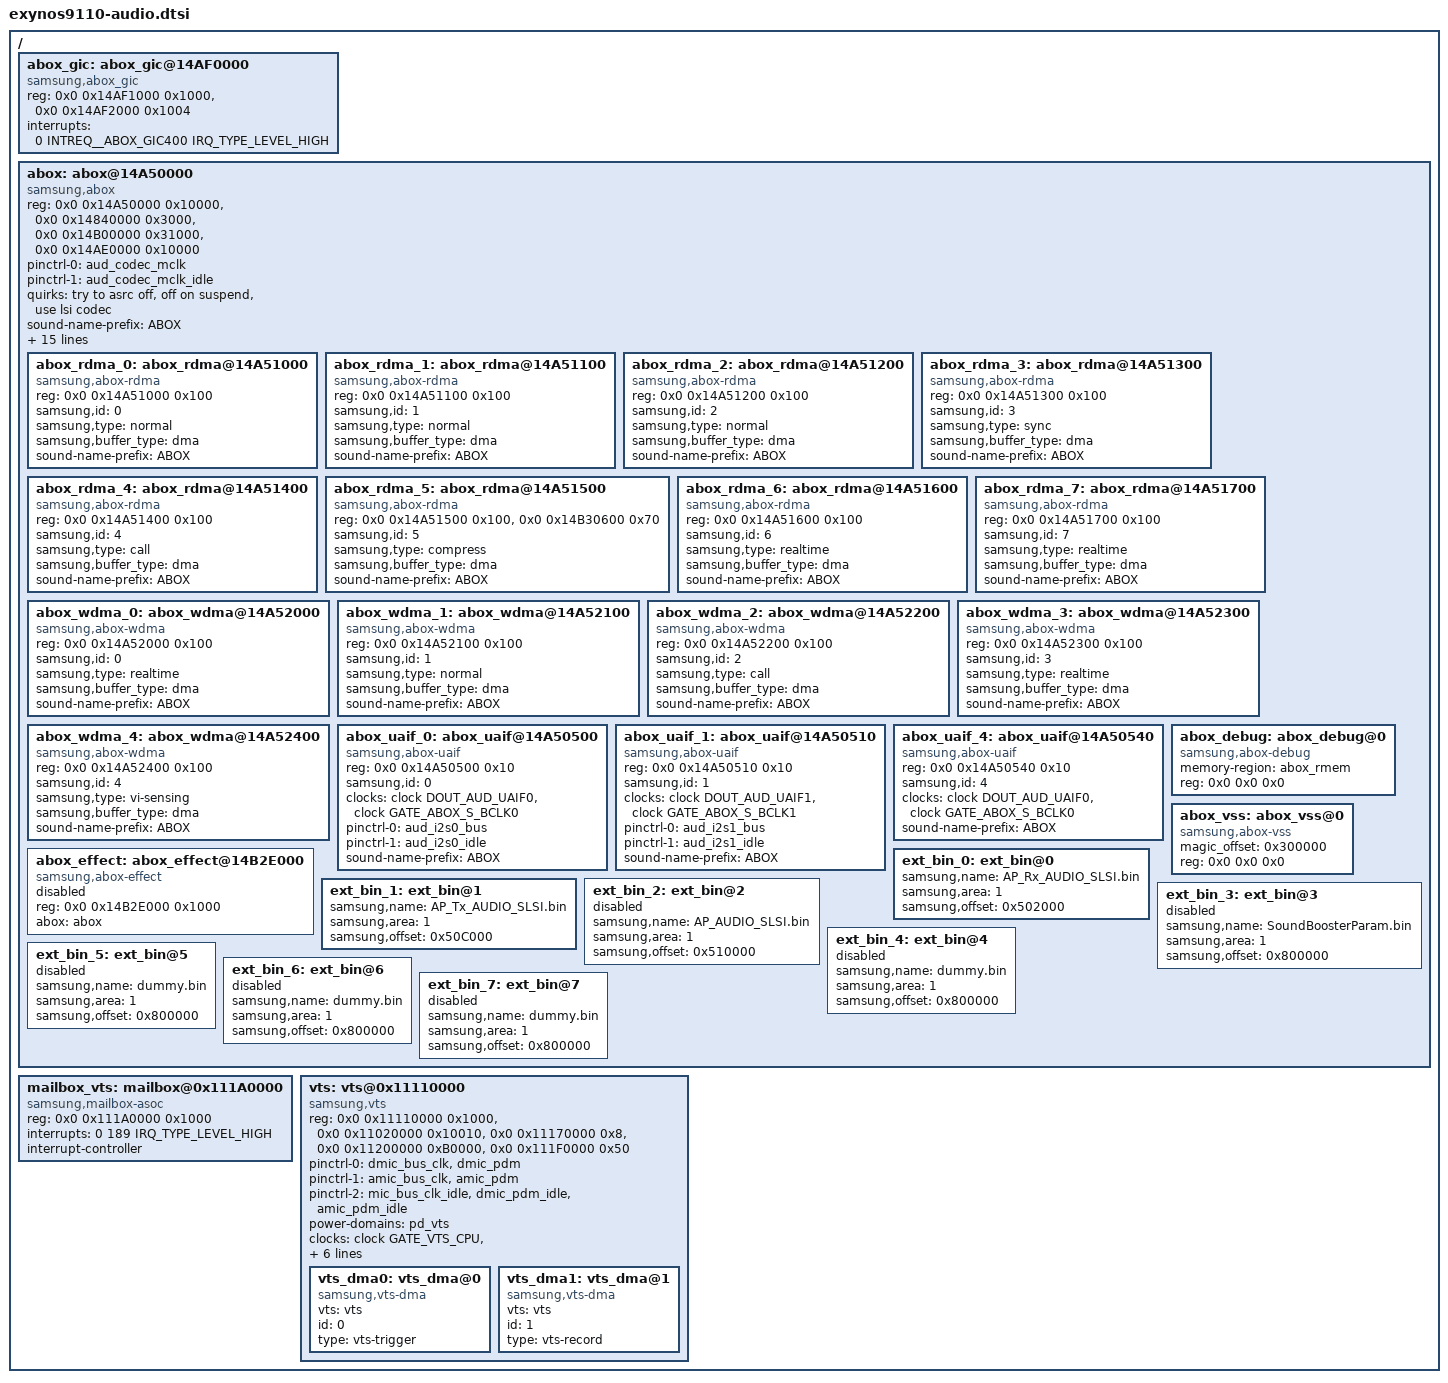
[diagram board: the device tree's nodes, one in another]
/*
 * SAMSUNG EXYNOS device tree source for reserved-memory
 *
 * Copyright (c) 2020 Samsung Electronics Co., Ltd.
 *		http://www.samsung.com
 *
 * This program is free software; you can redistribute it and/or modify
 * it under the terms of the GNU General Public License version 2 as
 * published by the Free Software Foundation.
 */

/ {
	abox_gic: abox_gic@14AF0000 {
		compatible = "samsung,abox_gic";
		reg = <0x0 0x14AF1000 0x1000>, <0x0 0x14AF2000 0x1004>;
		reg-names = "gicd", "gicc";
		interrupts = <0 INTREQ__ABOX_GIC400 IRQ_TYPE_LEVEL_HIGH>;
	};

	abox: abox@14A50000 {
		compatible = "samsung,abox";
		reg = <0x0 0x14A50000 0x10000>, <0x0 0x14840000 0x3000>,
			<0x0 0x14B00000 0x31000>, <0x0 0x14AE0000 0x10000>;
		reg-names = "sfr", "sysreg", "sram", "timer";
		#address-cells = <2>;
		#size-cells = <1>;
		ranges;
		pinctrl-names = "default", "idle";
		pinctrl-0 = <&aud_codec_mclk>;
		pinctrl-1 = <&aud_codec_mclk_idle>;
		quirks = "try to asrc off", "off on suspend", "use lsi codec";
		#sound-dai-cells = <1>;
		sound-name-prefix = "ABOX";
		samsung,power-domain = <&pd_dispaud>;
		ipc_tx_offset = <0x30000>;
		ipc_rx_offset = <0x30300>;
		ipc_tx_ack_offset = <0x302FC>;
		ipc_rx_ack_offset = <0x305FC>;
		abox_gic = <&abox_gic>;
		clocks = <&clock PLL_OUT_AUD>, <&clock GATE_ABOX_CPU>,
			<&clock DOUT_AUD_AUDIF>, <&clock DOUT_AUD_ACLK>;
		clock-names = "pll", "cpu", "audif", "bus";
		uaif_max_div = <512>;
		iommus = <&sysmmu_abox>;
		pm_qos_int = <0 0 0 0 0>;
		pm_qos_aud = <1180000 800000 590000 394000 0>;
		samsung,abox-bootargs = "init=ab0x vss=1";
		samsung,abox-bootargs-offset = <0x30E00>;

		abox_rdma_0: abox_rdma@14A51000 {
			compatible = "samsung,abox-rdma";
			reg = <0x0 0x14A51000 0x100>;
			reg-names = "sfr";
			samsung,id = <0>;
			samsung,type = "normal";
			samsung,buffer_type = "dma";
			#sound-dai-cells = <1>;
			sound-name-prefix = "ABOX";
		};

		abox_rdma_1: abox_rdma@14A51100 {
			compatible = "samsung,abox-rdma";
			reg = <0x0 0x14A51100 0x100>;
			reg-names = "sfr";
			samsung,id = <1>;
			samsung,type = "normal";
			samsung,buffer_type = "dma";
			#sound-dai-cells = <1>;
			sound-name-prefix = "ABOX";
		};

		abox_rdma_2: abox_rdma@14A51200 {
			compatible = "samsung,abox-rdma";
			reg = <0x0 0x14A51200 0x100>;
			reg-names = "sfr";
			samsung,id = <2>;
			samsung,type = "normal";
			samsung,buffer_type = "dma";
			#sound-dai-cells = <1>;
			sound-name-prefix = "ABOX";
		};

		abox_rdma_3: abox_rdma@14A51300 {
			compatible = "samsung,abox-rdma";
			reg = <0x0 0x14A51300 0x100>;
			reg-names = "sfr";
			samsung,id = <3>;
			samsung,type = "sync";
			samsung,buffer_type = "dma";
			#sound-dai-cells = <1>;
			sound-name-prefix = "ABOX";
		};

		abox_rdma_4: abox_rdma@14A51400 {
			compatible = "samsung,abox-rdma";
			reg = <0x0 0x14A51400 0x100>;
			reg-names = "sfr";
			samsung,id = <4>;
			samsung,type = "call";
			samsung,buffer_type = "dma";
			#sound-dai-cells = <1>;
			sound-name-prefix = "ABOX";
		};

		abox_rdma_5: abox_rdma@14A51500 {
			compatible = "samsung,abox-rdma";
			reg = <0x0 0x14A51500 0x100>, <0x0 0x14B30600 0x70>;
			reg-names = "sfr";
			samsung,id = <5>;
			samsung,type = "compress";
			samsung,buffer_type = "dma";
			#sound-dai-cells = <1>;
			sound-name-prefix = "ABOX";
		};

		abox_rdma_6: abox_rdma@14A51600 {
			compatible = "samsung,abox-rdma";
			reg = <0x0 0x14A51600 0x100>;
			reg-names = "sfr";
			samsung,id = <6>;
			samsung,type = "realtime";
			samsung,buffer_type = "dma";
			#sound-dai-cells = <1>;
			sound-name-prefix = "ABOX";
		};

		abox_rdma_7: abox_rdma@14A51700 {
			compatible = "samsung,abox-rdma";
			reg = <0x0 0x14A51700 0x100>;
			reg-names = "sfr";
			samsung,id = <7>;
			samsung,type = "realtime";
			samsung,buffer_type = "dma";
			#sound-dai-cells = <1>;
			sound-name-prefix = "ABOX";
		};

		abox_wdma_0: abox_wdma@14A52000 {
			compatible = "samsung,abox-wdma";
			reg = <0x0 0x14A52000 0x100>;
			reg-names = "sfr";
			samsung,id = <0>;
			samsung,type = "realtime";
			samsung,buffer_type = "dma";
			#sound-dai-cells = <1>;
			sound-name-prefix = "ABOX";
		};

		abox_wdma_1: abox_wdma@14A52100 {
			compatible = "samsung,abox-wdma";
			reg = <0x0 0x14A52100 0x100>;
			reg-names = "sfr";
			samsung,id = <1>;
			samsung,type = "normal";
			samsung,buffer_type = "dma";
			#sound-dai-cells = <1>;
			sound-name-prefix = "ABOX";
		};

		abox_wdma_2: abox_wdma@14A52200 {
			compatible = "samsung,abox-wdma";
			reg = <0x0 0x14A52200 0x100>;
			reg-names = "sfr";
			samsung,id = <2>;
			samsung,type = "call";
			samsung,buffer_type = "dma";
			#sound-dai-cells = <1>;
			sound-name-prefix = "ABOX";
		};

		abox_wdma_3: abox_wdma@14A52300 {
			compatible = "samsung,abox-wdma";
			reg = <0x0 0x14A52300 0x100>;
			reg-names = "sfr";
			samsung,id = <3>;
			samsung,type = "realtime";
			samsung,buffer_type = "dma";
			#sound-dai-cells = <1>;
			sound-name-prefix = "ABOX";
		};

		abox_wdma_4: abox_wdma@14A52400 {
			compatible = "samsung,abox-wdma";
			reg = <0x0 0x14A52400 0x100>;
			reg-names = "sfr";
			samsung,id = <4>;
			samsung,type = "vi-sensing";
			samsung,buffer_type = "dma";
			#sound-dai-cells = <1>;
			sound-name-prefix = "ABOX";
		};

		abox_uaif_0: abox_uaif@14A50500 {
			compatible = "samsung,abox-uaif";
			reg = <0x0 0x14A50500 0x10>;
			reg-names = "sfr";
			samsung,id = <0>;
			clocks = <&clock DOUT_AUD_UAIF0>, <&clock GATE_ABOX_S_BCLK0>;
			clock-names = "bclk", "bclk_gate";
			pinctrl-names = "default", "sleep";
			pinctrl-0 = <&aud_i2s0_bus>;
			pinctrl-1 = <&aud_i2s0_idle>;
			#sound-dai-cells = <0>;
			sound-name-prefix = "ABOX";
		};

		abox_uaif_1: abox_uaif@14A50510 {
			compatible = "samsung,abox-uaif";
			reg = <0x0 0x14A50510 0x10>;
			reg-names = "sfr";
			samsung,id = <1>;
			clocks = <&clock DOUT_AUD_UAIF1>, <&clock GATE_ABOX_S_BCLK1>;
			clock-names = "bclk", "bclk_gate";
			pinctrl-names = "default", "sleep";
			pinctrl-0 = <&aud_i2s1_bus>;
			pinctrl-1 = <&aud_i2s1_idle>;
			#sound-dai-cells = <0>;
			sound-name-prefix = "ABOX";
		};

		abox_uaif_4: abox_uaif@14A50540 {
			compatible = "samsung,abox-uaif";
			reg = <0x0 0x14A50540 0x10>;
			reg-names = "sfr";
			samsung,id = <4>;
			/* UAIF4 is connected to UAIF0 as slave */
			clocks = <&clock DOUT_AUD_UAIF0>, <&clock GATE_ABOX_S_BCLK0>;
			clock-names = "bclk", "bclk_gate";
			#sound-dai-cells = <0>;
			sound-name-prefix = "ABOX";
		};

		abox_effect: abox_effect@14B2E000 {
			status = "disabled";
			compatible = "samsung,abox-effect";
			reg = <0x0 0x14B2E000 0x1000>;
			reg-names = "reg";
			abox = <&abox>;
		};

		abox_debug: abox_debug@0 {
			compatible = "samsung,abox-debug";
			memory-region = <&abox_rmem>;
			reg = <0x0 0x0 0x0>;
		};

		abox_vss: abox_vss@0 {
			compatible = "samsung,abox-vss";
			magic_offset = <0x300000>;
			reg = <0x0 0x0 0x0>;
		};

		ext_bin_0: ext_bin@0 {
			status = "okay";
			samsung,name = "AP_Rx_AUDIO_SLSI.bin";
			samsung,area = <1>; /* 0:SRAM, 1:DRAM, 2:VSS */
			samsung,offset = <0x502000>;
		};
		ext_bin_1: ext_bin@1 {
			status = "okay";
			samsung,name = "AP_Tx_AUDIO_SLSI.bin";
			samsung,area = <1>;
			samsung,offset = <0x50C000>;
		};
		ext_bin_2: ext_bin@2 {
			status = "disabled";
			samsung,name = "AP_AUDIO_SLSI.bin";
			samsung,area = <1>;
			samsung,offset = <0x510000>;
		};
		ext_bin_3: ext_bin@3 {
			status = "disabled";
			samsung,name = "SoundBoosterParam.bin";
			samsung,area = <1>;
			samsung,offset = <0x800000>;
		};
		ext_bin_4: ext_bin@4 {
			status = "disabled";
			samsung,name = "dummy.bin";
			samsung,area = <1>;
			samsung,offset = <0x800000>;
		};
		ext_bin_5: ext_bin@5 {
			status = "disabled";
			samsung,name = "dummy.bin";
			samsung,area = <1>;
			samsung,offset = <0x800000>;
		};
		ext_bin_6: ext_bin@6 {
			status = "disabled";
			samsung,name = "dummy.bin";
			samsung,area = <1>;
			samsung,offset = <0x800000>;
		};
		ext_bin_7: ext_bin@7 {
			status = "disabled";
			samsung,name = "dummy.bin";
			samsung,area = <1>;
			samsung,offset = <0x800000>;
		};
	};

	mailbox_vts: mailbox@0x111A0000 {
		compatible = "samsung,mailbox-asoc";
		reg = <0x0 0x111A0000 0x1000>;
		reg-names = "sfr";
		interrupts = <0 189 IRQ_TYPE_LEVEL_HIGH>;
		interrupt-controller;
		#interrupt-cells = <1>;
	};

	vts: vts@0x11110000 {
		compatible = "samsung,vts";
		reg = <0x0 0x11110000 0x1000>, <0x0 0x11020000 0x10010>,
			<0x0 0x11170000 0x8>, <0x0 0x11200000 0xB0000>, <0x0 0x111F0000 0x50>;
		reg-names = "sfr", "baaw", "dmic", "sram", "gpr";
		#address-cells = <2>;
		#size-cells = <1>;
		ranges;
		pinctrl-names = "dmic_default", "amic_default", "idle";
		pinctrl-0 = <&dmic_bus_clk &dmic_pdm>;
		pinctrl-1 = <&amic_bus_clk &amic_pdm>;
		pinctrl-2 = <&mic_bus_clk_idle &dmic_pdm_idle &amic_pdm_idle>;
		power-domains = <&pd_vts>;
		#sound-dai-cells = <1>;
		clocks = <&clock GATE_VTS_CPU>, <&clock CLK_VTS_DMIC>,
			<&clock CLK_VTS_DMIC_IF>, <&clock CLK_VTS_DMIC_IF_DIV2>;
		clock-names = "rco", "dmic", "dmic_if", "dmic_sync";
		mailbox = <&mailbox_vts>;
		interrupt-parent = <&mailbox_vts>;
		sound-name-prefix = "VTS";
		interrupts = <0>, <1>, <2>, <3>, <4>, <5>, <6>, <7>, <8>, <9>;
		interrupt-names = "error", "boot_completed", "ipc_received", "voice_triggered",
				"trigger_period_elapsed", "record_period_elapsed",
				"debuglog_bufzero", "debuglog_bufone",
				"audio_dump", "log_dump";
		vts_dma0: vts_dma@0 {
			compatible = "samsung,vts-dma";
			vts = <&vts>;
			id = <0>;
			type = "vts-trigger";
			#sound-dai-cells = <1>;
		};

		vts_dma1: vts_dma@1 {
			compatible = "samsung,vts-dma";
			vts = <&vts>;
			id = <1>;
			type = "vts-record";
			#sound-dai-cells = <1>;
		};
	};
};
